# EFR32BG13P532F512GM32 register map
File version: 5.8.2
CPU: CM4 r0p1, little endian, MPU, FPU, 3 interrupt priority bits
Registers are 32-bit, read-write, reset 0x0 unless marked. A register's access mark holds for its fields unless they carry their own. Offsets are from the block's base; [hi:lo] are bit positions.

## FPU — Floting point unit
Base 0xE000EF34
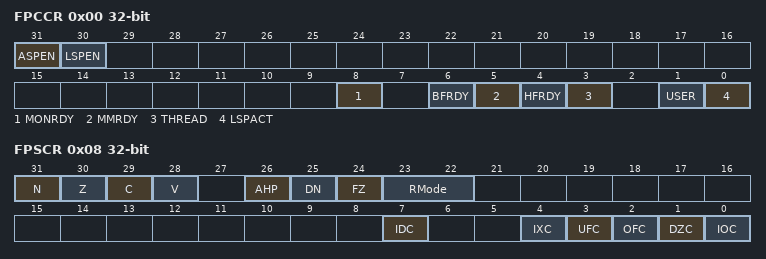
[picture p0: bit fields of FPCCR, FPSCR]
0x00 FPCCR — Floating-point context control register
  [31] ASPEN, [30] LSPEN, [8] MONRDY, [6] BFRDY, [5] MMRDY, [4] HFRDY, [3] THREAD, [1] USER, [0] LSPACT
0x04 FPCAR — Floating-point context address register
  [31:3] ADDRESS — Location of unpopulated floating-point
0x08 FPSCR — Floating-point status control register
  [31] N — Negative condition code flag
  [30] Z — Zero condition code flag
  [29] C — Carry condition code flag
  [28] V — Overflow condition code flag
  [26] AHP — Alternative half-precision control bit
  [25] DN — Default NaN mode control bit
  [24] FZ — Flush-to-zero mode control bit:
  [23:22] RMode — Rounding Mode control field
  [7] IDC — Input denormal cumulative exception bit.
  [4] IXC — Inexact cumulative exception bit
  [3] UFC — Underflow cumulative exception bit
  [2] OFC — Overflow cumulative exception bit
  [1] DZC — Division by zero cumulative exception bit.
  [0] IOC — Invalid operation cumulative exception bit

## MPU — Memory protection unit
Base 0xE000ED90
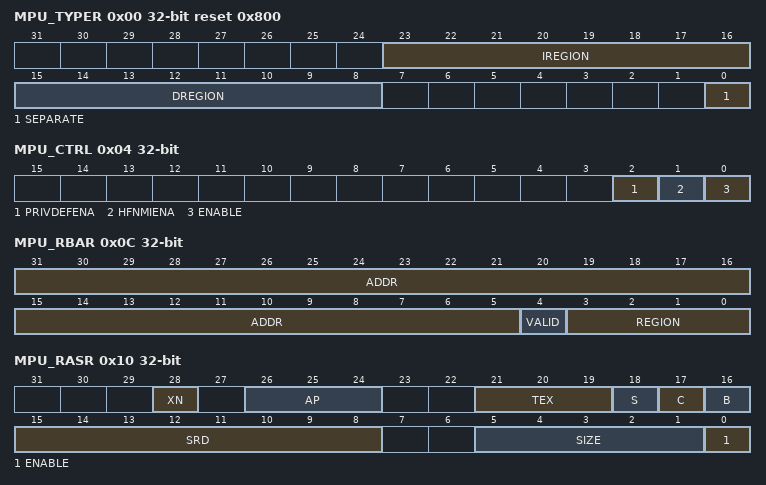
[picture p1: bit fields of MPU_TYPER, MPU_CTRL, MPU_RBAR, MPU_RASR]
0x00 MPU_TYPER ro reset 0x800 — MPU type register
  [23:16] IREGION — Number of MPU instruction regions
  [15:8] DREGION — Number of MPU data regions
  [0] SEPARATE — Separate flag
0x04 MPU_CTRL ro — MPU control register
  [2] PRIVDEFENA — Enable priviliged software access to default memory map
  [1] HFNMIENA — Enables the operation of MPU during hard fault
  [0] ENABLE — Enables the MPU
0x08 MPU_RNR — MPU region number register
  [7:0] REGION — MPU region
0x0C MPU_RBAR — MPU region base address register
  [31:5] ADDR — Region base address field
  [4] VALID — MPU region number valid
  [3:0] REGION — MPU region field
0x10 MPU_RASR — MPU region attribute and size register
  [28] XN — Instruction access disable bit
  [26:24] AP — Access permission
  [21:19] TEX — memory attribute
  [18] S — Shareable memory attribute
  [17] C — memory attribute
  [16] B — memory attribute
  [15:8] SRD — Subregion disable bits
  [5:1] SIZE — Size of the MPU protection region
  [0] ENABLE — Region enable bit.

## STK — SysTick timer
Base 0xE000E010
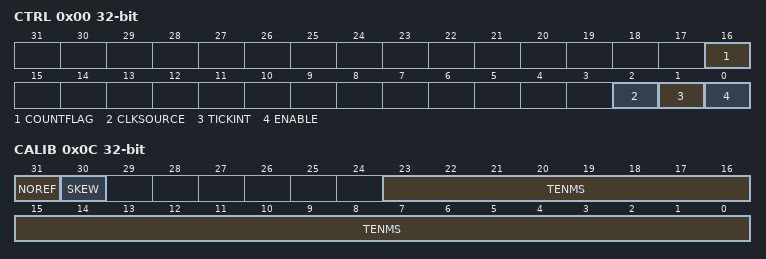
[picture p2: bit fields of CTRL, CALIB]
0x00 CTRL — SysTick control and status register
  [16] COUNTFLAG
  [2] CLKSOURCE — Clock source selection
  [1] TICKINT — SysTick exception request enable
  [0] ENABLE — Counter enable
0x04 LOAD — SysTick reload value register
  [23:0] RELOAD — RELOAD value
0x08 VAL — SysTick current value register
  [23:0] CURRENT — Current counter value
0x0C CALIB — SysTick calibration value register
  [31] NOREF — NOREF flag. Reads as zero
  [30] SKEW — SKEW flag: Indicates whether the TENMS value is exact
  [23:0] TENMS — Calibration value

## NVIC_ISER — Nested vectored interrupt controller
Base 0xE000E100
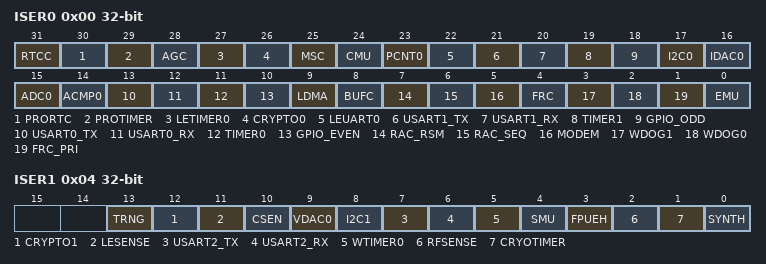
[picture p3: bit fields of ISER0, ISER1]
0x00 ISER0 — Interrupt Set Enable Register 0
  [31] RTCC — RTCC Interrupt
  [30] PRORTC — PRORTC Interrupt
  [29] PROTIMER — PROTIMER Interrupt
  [28] AGC — AGC Interrupt
  [27] LETIMER0 — LETIMER0 Interrupt
  [26] CRYPTO0 — CRYPTO0 Interrupt
  [25] MSC — MSC Interrupt
  [24] CMU — CMU Interrupt
  [23] PCNT0 — PCNT0 Interrupt
  [22] LEUART0 — LEUART0 Interrupt
  [21] USART1_TX — USART1_TX Interrupt
  [20] USART1_RX — USART1_RX Interrupt
  [19] TIMER1 — TIMER1 Interrupt
  [18] GPIO_ODD — GPIO_ODD Interrupt
  [17] I2C0 — I2C0 Interrupt
  [16] IDAC0 — IDAC0 Interrupt
  [15] ADC0 — ADC0 Interrupt
  [14] ACMP0 — ACMP0 Interrupt
  [13] USART0_TX — USART0_TX Interrupt
  [12] USART0_RX — USART0_RX Interrupt
  [11] TIMER0 — TIMER0 Interrupt
  [10] GPIO_EVEN — GPIO_EVEN Interrupt
  [9] LDMA — LDMA Interrupt
  [8] BUFC — BUFC Interrupt
  [7] RAC_RSM — RAC_RSM Interrupt
  [6] RAC_SEQ — RAC_SEQ Interrupt
  [5] MODEM — MODEM Interrupt
  [4] FRC — FRC Interrupt
  [3] WDOG1 — WDOG1 Interrupt
  [2] WDOG0 — WDOG0 Interrupt
  [1] FRC_PRI — FRC_PRI Interrupt
  [0] EMU — EMU Interrupt
0x04 ISER1 — Interrupt Set Enable Register 1
  [13] TRNG — TRNG Interrupt
  [12] CRYPTO1 — CRYPTO1 Interrupt
  [11] LESENSE — LESENSE Interrupt
  [10] CSEN — CSEN Interrupt
  [9] VDAC0 — VDAC0 Interrupt
  [8] I2C1 — I2C1 Interrupt
  [7] USART2_TX — USART2_TX Interrupt
  [6] USART2_RX — USART2_RX Interrupt
  [5] WTIMER0 — WTIMER0 Interrupt
  [4] SMU — SMU Interrupt
  [3] FPUEH — FPUEH Interrupt
  [2] RFSENSE — RFSENSE Interrupt
  [1] CRYOTIMER — CRYOTIMER Interrupt
  [0] SYNTH — SYNTH Interrupt
